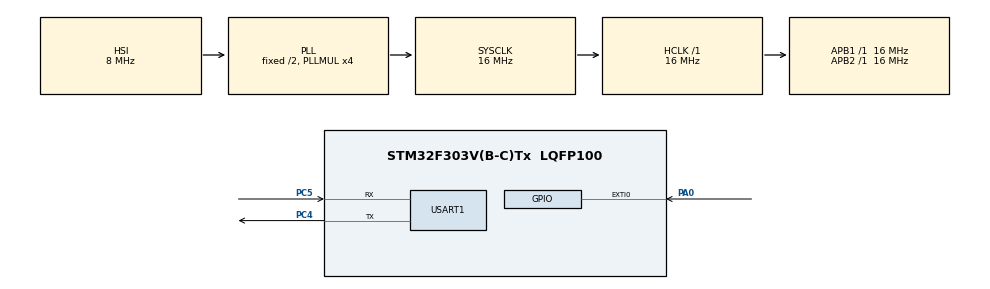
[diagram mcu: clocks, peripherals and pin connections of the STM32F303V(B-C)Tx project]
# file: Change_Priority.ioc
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FREERTOS.Tasks01=defaultTask,0,128,StartDefaultTask,Default,NULL,Dynamic,NULL,NULL;task1,1,128,StartTask01,Default,NULL,Dynamic,NULL,NULL;task2,2,128,StartTask02,Default,NULL,Dynamic,NULL,NULL
Mcu.Family=STM32F3
Mcu.Name=STM32F303V(B-C)Tx
Mcu.Package=LQFP100
NVIC.EXTI0_IRQn=true\:5\:0\:false\:false\:true\:true\:true\:true\:true
NVIC.PriorityGroup=NVIC_PRIORITYGROUP_4
PA0.Signal=GPXTI0
PC4.Mode=Asynchronous
PC4.Signal=USART1_TX
PC5.Mode=Asynchronous
PC5.Signal=USART1_RX
ProjectManager.HeapSize=0x200
ProjectManager.StackSize=0x400
ProjectManager.TargetToolchain=STM32CubeIDE
RCC.AHBFreq_Value=16000000
RCC.APB1Freq_Value=16000000
RCC.APB1TimFreq_Value=16000000
RCC.APB2Freq_Value=16000000
RCC.APB2TimFreq_Value=16000000
RCC.CortexFreq_Value=16000000
RCC.HCLKFreq_Value=16000000
RCC.HSE_VALUE=8000000
RCC.HSI_VALUE=8000000
RCC.LSE_VALUE=32768
RCC.PLLMUL=RCC_PLL_MUL4
RCC.SYSCLKFreq_VALUE=16000000
RCC.SYSCLKSourceVirtual=RCC_SYSCLKSOURCE_PLLCLK
RCC.USBFreq_Value=16000000
USART1.VirtualMode-Asynchronous=VM_ASYNC
VP_FREERTOS_VS_CMSIS_V1.Mode=CMSIS_V1
board=custom

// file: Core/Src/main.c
/* USER CODE BEGIN Header */
/**
  ******************************************************************************
  * @file           : main.c
  * @brief          : Main program body
  ******************************************************************************
  * @attention
  *
  * Copyright (c) 2023 STMicroelectronics.
  * All rights reserved.
  *
  * This software is licensed under terms that can be found in the LICENSE file
  * in the root directory of this software component.
  * If no LICENSE file comes with this software, it is provided AS-IS.
  *
  ******************************************************************************
  */
/* USER CODE END Header */
#include "main.h"
#include "cmsis_os.h"

/* USER CODE BEGIN Includes */
#include "stdio.h"
#include "string.h"
/* USER CODE END Includes */

UART_HandleTypeDef huart1;

osThreadId defaultTaskHandle;
osThreadId task1Handle;
osThreadId task2Handle;
/* USER CODE BEGIN PV */

uint8_t count=0;
char msg[50];

/* USER CODE END PV */

void SystemClock_Config(void);
static void MX_GPIO_Init(void);
static void MX_USART1_UART_Init(void);
void StartDefaultTask(void const * argument);
void StartTask01(void const * argument);
void StartTask02(void const * argument);

/* USER CODE BEGIN PFP */
void EXTI0_IRQHandler(void)
{

	if(HAL_GPIO_ReadPin(GPIOA, GPIO_PIN_0)==GPIO_PIN_SET){

		while(HAL_GPIO_ReadPin(GPIOA, GPIO_PIN_0)==GPIO_PIN_SET);

		count=1;

	}

	HAL_GPIO_EXTI_IRQHandler(GPIO_PIN_0);

}
/* USER CODE END PFP */

int main(void)
{

  /* MCU Configuration--------------------------------------------------------*/

  /* Reset of all peripherals, Initializes the Flash interface and the Systick. */
  HAL_Init();

  /* Configure the system clock */
  SystemClock_Config();

  /* Initialize all configured peripherals */
  MX_GPIO_Init();
  MX_USART1_UART_Init();

  /* Create the thread(s) */
  /* definition and creation of defaultTask */
  osThreadDef(defaultTask, StartDefaultTask, osPriorityNormal, 0, 128);
  defaultTaskHandle = osThreadCreate(osThread(defaultTask), NULL);

  /* definition and creation of task1 */
  osThreadDef(task1, StartTask01, osPriorityAboveNormal, 0, 128);
  task1Handle = osThreadCreate(osThread(task1), NULL);

  /* definition and creation of task2 */
  osThreadDef(task2, StartTask02, osPriorityHigh, 0, 128);
  task2Handle = osThreadCreate(osThread(task2), NULL);

  /* Start scheduler */
  osKernelStart();
  /* We should never get here as control is now taken by the scheduler */
  /* Infinite loop */
  while (1)
  {

  }
}

void SystemClock_Config(void)
{
  RCC_OscInitTypeDef RCC_OscInitStruct = {0};
  RCC_ClkInitTypeDef RCC_ClkInitStruct = {0};
  RCC_PeriphCLKInitTypeDef PeriphClkInit = {0};

  /** Initializes the RCC Oscillators according to the specified parameters
  * in the RCC_OscInitTypeDef structure.
  */
  RCC_OscInitStruct.OscillatorType = RCC_OSCILLATORTYPE_HSI;
  RCC_OscInitStruct.HSIState = RCC_HSI_ON;
  RCC_OscInitStruct.HSICalibrationValue = RCC_HSICALIBRATION_DEFAULT;
  RCC_OscInitStruct.PLL.PLLState = RCC_PLL_ON;
  RCC_OscInitStruct.PLL.PLLSource = RCC_PLLSOURCE_HSI;
  RCC_OscInitStruct.PLL.PLLMUL = RCC_PLL_MUL4;
  if (HAL_RCC_OscConfig(&RCC_OscInitStruct) != HAL_OK)
  {
    Error_Handler();
  }

  /** Initializes the CPU, AHB and APB buses clocks
  */
  RCC_ClkInitStruct.ClockType = RCC_CLOCKTYPE_HCLK|RCC_CLOCKTYPE_SYSCLK
                              |RCC_CLOCKTYPE_PCLK1|RCC_CLOCKTYPE_PCLK2;
  RCC_ClkInitStruct.SYSCLKSource = RCC_SYSCLKSOURCE_PLLCLK;
  RCC_ClkInitStruct.AHBCLKDivider = RCC_SYSCLK_DIV1;
  RCC_ClkInitStruct.APB1CLKDivider = RCC_HCLK_DIV1;
  RCC_ClkInitStruct.APB2CLKDivider = RCC_HCLK_DIV1;

  if (HAL_RCC_ClockConfig(&RCC_ClkInitStruct, FLASH_LATENCY_0) != HAL_OK)
  {
    Error_Handler();
  }
  PeriphClkInit.PeriphClockSelection = RCC_PERIPHCLK_USART1;
  PeriphClkInit.Usart1ClockSelection = RCC_USART1CLKSOURCE_PCLK2;
  if (HAL_RCCEx_PeriphCLKConfig(&PeriphClkInit) != HAL_OK)
  {
    Error_Handler();
  }
}

static void MX_USART1_UART_Init(void)
{

  huart1.Instance = USART1;
  huart1.Init.BaudRate = 38400;
  huart1.Init.WordLength = UART_WORDLENGTH_8B;
  huart1.Init.StopBits = UART_STOPBITS_1;
  huart1.Init.Parity = UART_PARITY_NONE;
  huart1.Init.Mode = UART_MODE_TX_RX;
  huart1.Init.HwFlowCtl = UART_HWCONTROL_NONE;
  huart1.Init.OverSampling = UART_OVERSAMPLING_16;
  huart1.Init.OneBitSampling = UART_ONE_BIT_SAMPLE_DISABLE;
  huart1.AdvancedInit.AdvFeatureInit = UART_ADVFEATURE_NO_INIT;
  if (HAL_UART_Init(&huart1) != HAL_OK)
  {
    Error_Handler();
  }

}

static void MX_GPIO_Init(void)
{
  GPIO_InitTypeDef GPIO_InitStruct = {0};

  /* GPIO Ports Clock Enable */
  __HAL_RCC_GPIOA_CLK_ENABLE();
  __HAL_RCC_GPIOC_CLK_ENABLE();

  /*Configure GPIO pin : PA0 */
  GPIO_InitStruct.Pin = GPIO_PIN_0;
  GPIO_InitStruct.Mode = GPIO_MODE_IT_RISING;
  GPIO_InitStruct.Pull = GPIO_NOPULL;
  HAL_GPIO_Init(GPIOA, &GPIO_InitStruct);

  /* EXTI interrupt init*/
  HAL_NVIC_SetPriority(EXTI0_IRQn, 5, 0);
  HAL_NVIC_EnableIRQ(EXTI0_IRQn);

}

void StartDefaultTask(void const * argument)
{
  for(;;)
  {
    osDelay(1);
  }
}

void StartTask01(void const * argument)
{
  /* USER CODE BEGIN StartTask01 */
  /* Infinite loop */

	osPriority task1prio,task2prio;
//
//		sprintf(msg,"Task1 is runnig \r\n");
//		HAL_UART_Transmit(&huart1, (uint8_t*)msg, strlen(msg), 1000);

  for(;;)
  {

		sprintf(msg,"Task1 is runnig \r\n");
		HAL_UART_Transmit(&huart1, (uint8_t*)msg, strlen(msg), 1000);
		sprintf(msg,"Task1 priority=%d \r\n",osThreadGetPriority(task1Handle));
		HAL_UART_Transmit(&huart1, (uint8_t*)msg, strlen(msg), 1000);
		sprintf(msg,"Task2 priority=%d \r\n",osThreadGetPriority(task2Handle));
		HAL_UART_Transmit(&huart1, (uint8_t*)msg, strlen(msg), 1000);
		HAL_Delay(2000);
		if(count==1){
			count=0;

			task1prio=osThreadGetPriority(task1Handle);
			task2prio=osThreadGetPriority(task2Handle);
			osThreadSetPriority(task1Handle, task2prio);
			osThreadSetPriority(task2Handle, task1prio);

		}

  }
  /* USER CODE END StartTask01 */
}

void StartTask02(void const * argument)
{
  /* USER CODE BEGIN StartTask02 */
  /* Infinite loop */

	osPriority task1prio,task2prio;

//		sprintf(msg,"Task2 is runnig \r\n");
//		HAL_UART_Transmit(&huart1, (uint8_t*)msg, strlen(msg), 1000);

  for(;;)
  {

		sprintf(msg,"Task2 is runnig \r\n");
		HAL_UART_Transmit(&huart1, (uint8_t*)msg, strlen(msg), 1000);
		sprintf(msg,"Task1 priority=%d \r\n",osThreadGetPriority(task1Handle));
			HAL_UART_Transmit(&huart1, (uint8_t*)msg, strlen(msg), 1000);
			sprintf(msg,"Task2 priority=%d \r\n",osThreadGetPriority(task2Handle));
			HAL_UART_Transmit(&huart1, (uint8_t*)msg, strlen(msg), 1000);
		HAL_Delay(2000);
		if(count==1){

			count=0;

			task1prio=osThreadGetPriority(task1Handle);
					task2prio=osThreadGetPriority(task2Handle);

					osThreadSetPriority(task1Handle, task2prio);
					osThreadSetPriority(task2Handle, task1prio);

		}
  }
  /* USER CODE END StartTask02 */
}

void Error_Handler(void)
{
  __disable_irq();
  while (1)
  {
  }
}
